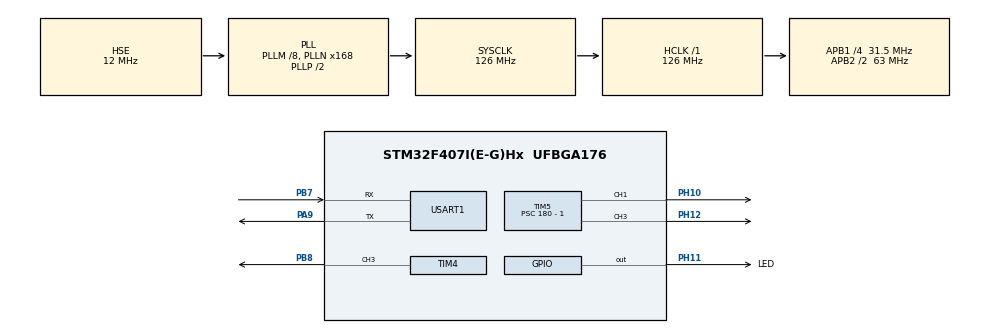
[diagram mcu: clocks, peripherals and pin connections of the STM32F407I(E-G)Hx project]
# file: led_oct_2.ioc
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Mcu.Family=STM32F4
Mcu.Name=STM32F407I(E-G)Hx
Mcu.Package=UFBGA176
NVIC.PriorityGroup=NVIC_PRIORITYGROUP_4
NVIC.USART1_IRQn=true\:2\:0\:true\:false\:true\:true\:true\:true
PA13.Mode=Serial_Wire
PA13.Signal=SYS_JTMS-SWDIO
PA14.Mode=Serial_Wire
PA14.Signal=SYS_JTCK-SWCLK
PA9.Mode=Asynchronous
PA9.Signal=USART1_TX
PB7.Mode=Asynchronous
PB7.Signal=USART1_RX
PB8.Signal=S_TIM4_CH3
PH0-OSC_IN.Mode=HSE-External-Oscillator
PH0-OSC_IN.Signal=RCC_OSC_IN
PH1-OSC_OUT.Mode=HSE-External-Oscillator
PH1-OSC_OUT.Signal=RCC_OSC_OUT
PH10.Signal=S_TIM5_CH1
PH11.GPIO_Label=LED
PH11.GPIO_PuPd=GPIO_PULLUP
PH11.Signal=GPIO_Output
PH12.GPIO_ModeDefaultPP=GPIO_MODE_AF_PP
PH12.GPIO_PuPd=GPIO_NOPULL
PH12.GPIO_Speed=GPIO_SPEED_FREQ_LOW
PH12.Signal=S_TIM5_CH3
ProjectManager.HeapSize=0x200
ProjectManager.StackSize=0x400
ProjectManager.TargetToolchain=MDK-ARM V5.32
RCC.48MHZClocksFreq_Value=63000000
RCC.AHBFreq_Value=126000000
RCC.APB1CLKDivider=RCC_HCLK_DIV4
RCC.APB1Freq_Value=31500000
RCC.APB1TimFreq_Value=63000000
RCC.APB2CLKDivider=RCC_HCLK_DIV2
RCC.APB2Freq_Value=63000000
RCC.APB2TimFreq_Value=126000000
RCC.CortexFreq_Value=126000000
RCC.HCLKFreq_Value=126000000
RCC.HSE_VALUE=12000000
RCC.HSI_VALUE=16000000
RCC.LSE_VALUE=32768
RCC.PLLM=8
RCC.PLLN=168
RCC.PLLSourceVirtual=RCC_PLLSOURCE_HSE
RCC.SYSCLKFreq_VALUE=126000000
RCC.SYSCLKSource=RCC_SYSCLKSOURCE_PLLCLK
RCC.VCOOutputFreq_Value=252000000
SH.S_TIM4_CH3.0=TIM4_CH3,PWM Generation3 CH3
SH.S_TIM5_CH1.0=TIM5_CH1,PWM Generation1 CH1
SH.S_TIM5_CH3.0=TIM5_CH3,PWM Generation3 CH3
TIM1.Period=1000 - 1
TIM1.Prescaler=180 - 1
TIM4.Channel-PWM\ Generation3\ CH3=TIM_CHANNEL_3
TIM4.Period=180 - 1
TIM4.Prescaler=1000 - 1
TIM4.Pulse-PWM\ Generation3\ CH3=500 - 1
TIM5.Channel-PWM\ Generation1\ CH1=TIM_CHANNEL_1
TIM5.Channel-PWM\ Generation3\ CH3=TIM_CHANNEL_3
TIM5.OCMode_PWM-PWM\ Generation3\ CH3=TIM_OCMODE_PWM2
TIM5.Period=1000 - 1
TIM5.Prescaler=180 - 1
TIM5.Pulse-PWM\ Generation3\ CH3=500 - 1
USART1.Parity=PARITY_EVEN
USART1.VirtualMode=VM_ASYNC
USART1.WordLength=WORDLENGTH_9B
VP_TIM1_VS_ClockSourceINT.Mode=Internal
VP_TIM4_VS_ClockSourceINT.Mode=Internal
VP_TIM5_VS_ClockSourceINT.Mode=Internal
board=custom

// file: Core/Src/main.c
/* USER CODE BEGIN Header */
/**
  ******************************************************************************
  * @file           : main.c
  * @brief          : Main program body
  ******************************************************************************
  * @attention
  *
  * Copyright (c) 2025 STMicroelectronics.
  * All rights reserved.
  *
  * This software is licensed under terms that can be found in the LICENSE file
  * in the root directory of this software component.
  * If no LICENSE file comes with this software, it is provided AS-IS.
  *
  ******************************************************************************
  */
/* USER CODE END Header */
#include "main.h"
#include "tim.h"
#include "usart.h"
#include "gpio.h"

/* USER CODE BEGIN Includes */
#include<math.h>
/* USER CODE END Includes */

/* USER CODE BEGIN PV */
uint32_t ticks;
uint8_t status = 0;
uint8_t tx_msg[] = "RoboMaster";
uint8_t rx_msg[10];
/* USER CODE END PV */

void SystemClock_Config(void);

int main(void)
{

  /* MCU Configuration--------------------------------------------------------*/

  /* Reset of all peripherals, Initializes the Flash interface and the Systick. */
  HAL_Init();

  /* Configure the system clock */
  SystemClock_Config();

  /* Initialize all configured peripherals */
  MX_GPIO_Init();
  MX_TIM1_Init();
  MX_TIM5_Init();
  MX_TIM4_Init();
  MX_USART1_UART_Init();
  /* USER CODE BEGIN 2 */
  HAL_UART_Receive_IT(&huart1, rx_msg, 1);
  /* USER CODE END 2 */

  /* Infinite loop */
  /* USER CODE BEGIN WHILE */
  while (1)
  {
    HAL_UART_Transmit(&huart1, tx_msg, 10, 1000);
    HAL_Delay(1000);
    /* USER CODE END WHILE */

  }
}

void SystemClock_Config(void)
{
  RCC_OscInitTypeDef RCC_OscInitStruct = {0};
  RCC_ClkInitTypeDef RCC_ClkInitStruct = {0};

  /** Configure the main internal regulator output voltage
  */
  __HAL_RCC_PWR_CLK_ENABLE();
  __HAL_PWR_VOLTAGESCALING_CONFIG(PWR_REGULATOR_VOLTAGE_SCALE1);

  /** Initializes the RCC Oscillators according to the specified parameters
  * in the RCC_OscInitTypeDef structure.
  */
  RCC_OscInitStruct.OscillatorType = RCC_OSCILLATORTYPE_HSE;
  RCC_OscInitStruct.HSEState = RCC_HSE_ON;
  RCC_OscInitStruct.PLL.PLLState = RCC_PLL_ON;
  RCC_OscInitStruct.PLL.PLLSource = RCC_PLLSOURCE_HSE;
  RCC_OscInitStruct.PLL.PLLM = 8;
  RCC_OscInitStruct.PLL.PLLN = 168;
  RCC_OscInitStruct.PLL.PLLP = RCC_PLLP_DIV2;
  RCC_OscInitStruct.PLL.PLLQ = 4;
  if (HAL_RCC_OscConfig(&RCC_OscInitStruct) != HAL_OK)
  {
    Error_Handler();
  }

  /** Initializes the CPU, AHB and APB buses clocks
  */
  RCC_ClkInitStruct.ClockType = RCC_CLOCKTYPE_HCLK|RCC_CLOCKTYPE_SYSCLK
                              |RCC_CLOCKTYPE_PCLK1|RCC_CLOCKTYPE_PCLK2;
  RCC_ClkInitStruct.SYSCLKSource = RCC_SYSCLKSOURCE_PLLCLK;
  RCC_ClkInitStruct.AHBCLKDivider = RCC_SYSCLK_DIV1;
  RCC_ClkInitStruct.APB1CLKDivider = RCC_HCLK_DIV4;
  RCC_ClkInitStruct.APB2CLKDivider = RCC_HCLK_DIV2;

  if (HAL_RCC_ClockConfig(&RCC_ClkInitStruct, FLASH_LATENCY_4) != HAL_OK)
  {
    Error_Handler();
  }
}

void Error_Handler(void)
{
  __disable_irq();
  while (1)
  {
  }
}
